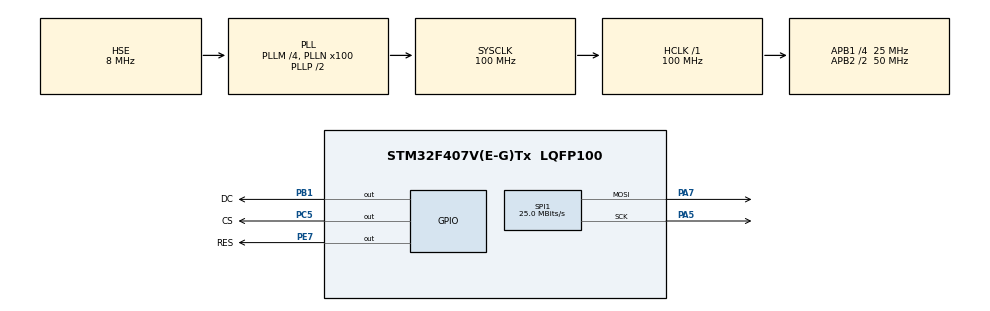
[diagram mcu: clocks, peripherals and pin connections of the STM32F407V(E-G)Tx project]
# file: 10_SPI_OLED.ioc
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Mcu.Family=STM32F4
RCC.PLLSourceVirtual=RCC_PLLSOURCE_HSE
PH0-OSC_IN.Signal=RCC_OSC_IN
RCC.CortexFreq_Value=100000000
PA7.Mode=TX_Only_Simplex_Unidirect_Master
SPI1.VirtualType=VM_MASTER
SPI1.CLKPhase=SPI_PHASE_2EDGE
RCC.APB1CLKDivider=RCC_HCLK_DIV4
RCC.SYSCLKSource=RCC_SYSCLKSOURCE_PLLCLK
ProjectManager.StackSize=0x400
SPI1.CLKPolarity=SPI_POLARITY_HIGH
ProjectManager.TargetToolchain=STM32CubeIDE
SPI1.Direction=SPI_DIRECTION_2LINES
RCC.HCLKFreq_Value=100000000
RCC.APB2TimFreq_Value=100000000
SPI1.CalculateBaudRate=25.0 MBits/s
RCC.LSE_VALUE=32768
RCC.AHBFreq_Value=100000000
PH0-OSC_IN.Mode=HSE-External-Oscillator
PA5.Signal=SPI1_SCK
RCC.HSE_VALUE=8000000
board=STM32F407G-DISC1
RCC.VCOOutputFreq_Value=200000000
RCC.APB2Freq_Value=50000000
SPI1.Mode=SPI_MODE_MASTER
PB1.GPIO_Label=DC
PH1-OSC_OUT.Signal=RCC_OSC_OUT
Mcu.Name=STM32F407V(E-G)Tx
PE7.GPIO_Label=RES
PH1-OSC_OUT.Mode=HSE-External-Oscillator
RCC.48MHZClocksFreq_Value=28571428.57142857
RCC.SYSCLKFreq_VALUE=100000000
Mcu.Package=LQFP100
PB1.Signal=GPIO_Output
PC5.GPIO_Label=CS
ProjectManager.HeapSize=0x200
RCC.HSI_VALUE=16000000
RCC.PLLQ=7
NVIC.PriorityGroup=NVIC_PRIORITYGROUP_0
RCC.APB2CLKDivider=RCC_HCLK_DIV2
RCC.PLLM=4
RCC.PLLN=100
RCC.APB1TimFreq_Value=50000000
PC5.Signal=GPIO_Output
PE7.Signal=GPIO_Output
RCC.APB1Freq_Value=25000000
PA7.Signal=SPI1_MOSI
PA5.Mode=TX_Only_Simplex_Unidirect_Master

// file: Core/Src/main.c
/* USER CODE BEGIN Header */
/**
  ******************************************************************************
  * @file           : main.c
  * @brief          : Main program body
  ******************************************************************************
  * @attention
  *
  * <h2><center>&copy; Copyright (c) 2021 STMicroelectronics.
  * All rights reserved.</center></h2>
  *
  * This software component is licensed by ST under BSD 3-Clause license,
  * the "License"; You may not use this file except in compliance with the
  * License. You may obtain a copy of the License at:
  *                        opensource.org/licenses/BSD-3-Clause
  *
  ******************************************************************************
  */
/* USER CODE END Header */
#include "main.h"

/* USER CODE BEGIN Includes */
#include "SSD1331.h"
/* USER CODE END Includes */

SPI_HandleTypeDef hspi1;

void SystemClock_Config(void);
static void MX_GPIO_Init(void);
static void MX_SPI1_Init(void);

int main(void)
{

  /* MCU Configuration--------------------------------------------------------*/

  /* Reset of all peripherals, Initializes the Flash interface and the Systick. */
  HAL_Init();

  /* Configure the system clock */
  SystemClock_Config();

  /* Initialize all configured peripherals */
  MX_GPIO_Init();
  MX_SPI1_Init();
  /* USER CODE BEGIN 2 */
  ssd1331_init();
//  ssd1331_draw_1616char(0,0,4,WHITE);
  ssd1331_clear_screen(BLACK);
  ssd1331_display_string(0, 0, "Hello World!", FONT_1608, WHITE);
  /* USER CODE END 2 */

  /* Infinite loop */
  while (1)
  {

  }
}

void SystemClock_Config(void)
{
  RCC_OscInitTypeDef RCC_OscInitStruct = {0};
  RCC_ClkInitTypeDef RCC_ClkInitStruct = {0};

  /** Configure the main internal regulator output voltage
  */
  __HAL_RCC_PWR_CLK_ENABLE();
  __HAL_PWR_VOLTAGESCALING_CONFIG(PWR_REGULATOR_VOLTAGE_SCALE1);
  /** Initializes the RCC Oscillators according to the specified parameters
  * in the RCC_OscInitTypeDef structure.
  */
  RCC_OscInitStruct.OscillatorType = RCC_OSCILLATORTYPE_HSE;
  RCC_OscInitStruct.HSEState = RCC_HSE_ON;
  RCC_OscInitStruct.PLL.PLLState = RCC_PLL_ON;
  RCC_OscInitStruct.PLL.PLLSource = RCC_PLLSOURCE_HSE;
  RCC_OscInitStruct.PLL.PLLM = 4;
  RCC_OscInitStruct.PLL.PLLN = 100;
  RCC_OscInitStruct.PLL.PLLP = RCC_PLLP_DIV2;
  RCC_OscInitStruct.PLL.PLLQ = 7;
  if (HAL_RCC_OscConfig(&RCC_OscInitStruct) != HAL_OK)
  {
    Error_Handler();
  }
  /** Initializes the CPU, AHB and APB buses clocks
  */
  RCC_ClkInitStruct.ClockType = RCC_CLOCKTYPE_HCLK|RCC_CLOCKTYPE_SYSCLK
                              |RCC_CLOCKTYPE_PCLK1|RCC_CLOCKTYPE_PCLK2;
  RCC_ClkInitStruct.SYSCLKSource = RCC_SYSCLKSOURCE_PLLCLK;
  RCC_ClkInitStruct.AHBCLKDivider = RCC_SYSCLK_DIV1;
  RCC_ClkInitStruct.APB1CLKDivider = RCC_HCLK_DIV4;
  RCC_ClkInitStruct.APB2CLKDivider = RCC_HCLK_DIV2;

  if (HAL_RCC_ClockConfig(&RCC_ClkInitStruct, FLASH_LATENCY_3) != HAL_OK)
  {
    Error_Handler();
  }
}

static void MX_SPI1_Init(void)
{

  /* SPI1 parameter configuration*/
  hspi1.Instance = SPI1;
  hspi1.Init.Mode = SPI_MODE_MASTER;
  hspi1.Init.Direction = SPI_DIRECTION_2LINES;
  hspi1.Init.DataSize = SPI_DATASIZE_8BIT;
  hspi1.Init.CLKPolarity = SPI_POLARITY_HIGH;
  hspi1.Init.CLKPhase = SPI_PHASE_2EDGE;
  hspi1.Init.NSS = SPI_NSS_SOFT;
  hspi1.Init.BaudRatePrescaler = SPI_BAUDRATEPRESCALER_2;
  hspi1.Init.FirstBit = SPI_FIRSTBIT_MSB;
  hspi1.Init.TIMode = SPI_TIMODE_DISABLE;
  hspi1.Init.CRCCalculation = SPI_CRCCALCULATION_DISABLE;
  hspi1.Init.CRCPolynomial = 10;
  if (HAL_SPI_Init(&hspi1) != HAL_OK)
  {
    Error_Handler();
  }

}

static void MX_GPIO_Init(void)
{
  GPIO_InitTypeDef GPIO_InitStruct = {0};

  /* GPIO Ports Clock Enable */
  __HAL_RCC_GPIOH_CLK_ENABLE();
  __HAL_RCC_GPIOA_CLK_ENABLE();
  __HAL_RCC_GPIOC_CLK_ENABLE();
  __HAL_RCC_GPIOB_CLK_ENABLE();
  __HAL_RCC_GPIOE_CLK_ENABLE();

  /*Configure GPIO pin Output Level */
  HAL_GPIO_WritePin(CS_GPIO_Port, CS_Pin, GPIO_PIN_RESET);

  /*Configure GPIO pin Output Level */
  HAL_GPIO_WritePin(DC_GPIO_Port, DC_Pin, GPIO_PIN_RESET);

  /*Configure GPIO pin Output Level */
  HAL_GPIO_WritePin(RES_GPIO_Port, RES_Pin, GPIO_PIN_RESET);

  /*Configure GPIO pin : CS_Pin */
  GPIO_InitStruct.Pin = CS_Pin;
  GPIO_InitStruct.Mode = GPIO_MODE_OUTPUT_PP;
  GPIO_InitStruct.Pull = GPIO_NOPULL;
  GPIO_InitStruct.Speed = GPIO_SPEED_FREQ_LOW;
  HAL_GPIO_Init(CS_GPIO_Port, &GPIO_InitStruct);

  /*Configure GPIO pin : DC_Pin */
  GPIO_InitStruct.Pin = DC_Pin;
  GPIO_InitStruct.Mode = GPIO_MODE_OUTPUT_PP;
  GPIO_InitStruct.Pull = GPIO_NOPULL;
  GPIO_InitStruct.Speed = GPIO_SPEED_FREQ_LOW;
  HAL_GPIO_Init(DC_GPIO_Port, &GPIO_InitStruct);

  /*Configure GPIO pin : RES_Pin */
  GPIO_InitStruct.Pin = RES_Pin;
  GPIO_InitStruct.Mode = GPIO_MODE_OUTPUT_PP;
  GPIO_InitStruct.Pull = GPIO_NOPULL;
  GPIO_InitStruct.Speed = GPIO_SPEED_FREQ_LOW;
  HAL_GPIO_Init(RES_GPIO_Port, &GPIO_InitStruct);

}

void Error_Handler(void)
{
  __disable_irq();
  while (1)
  {
  }
}

/************************ (C) COPYRIGHT STMicroelectronics *****END OF FILE****/
